VERSION ""

NS_ :

BS_:

BU_: DCU
VAL_TABLE_ OpCodeInfo 3 "MaxOpCodeIndex" 2 "SnrsFaultCodes" 1 "HWFaultCodes" 0 "InverterState" ;
VAL_TABLE_ OpCodeSignal 11 "MaxOpCodeIndex" 10 "DQAxesVoltages" 9 "PowerMeterInfo" 8 "PhaseVoltages" 7 "DQAxesCurrents" 6 "SpeedRefFdbck" 5 "TorqueRefFdbck" 4 "SpeedAndPosition" 3 "MeasuredVoltages" 2 "MeasuredCurrents" 1 "ExternalTemper" 0 "InternalTemper" ;

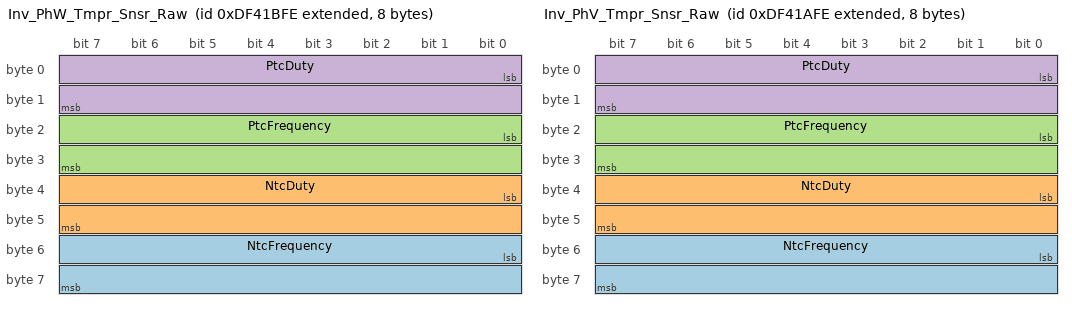
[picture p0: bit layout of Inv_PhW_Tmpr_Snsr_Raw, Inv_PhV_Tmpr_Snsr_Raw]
BO_ 2381585406 Inv_PhW_Tmpr_Snsr_Raw: 8 Vector__XXX
 SG_ NtcFrequency : 48|16@1+ (1,0) [0|65535] "" Vector__XXX
 SG_ NtcDuty : 32|16@1+ (1,0) [0|65535] "" Vector__XXX
 SG_ PtcFrequency : 16|16@1+ (1,0) [0|65535] "" Vector__XXX
 SG_ PtcDuty : 0|16@1+ (1,0) [0|65535] "" Vector__XXX

BO_ 2381585150 Inv_PhV_Tmpr_Snsr_Raw: 8 Vector__XXX
 SG_ NtcFrequency : 48|16@1+ (1,0) [0|65535] "" Vector__XXX
 SG_ NtcDuty : 32|16@1+ (1,0) [0|65535] "" Vector__XXX
 SG_ PtcFrequency : 16|16@1+ (1,0) [0|65535] "" Vector__XXX
 SG_ PtcDuty : 0|16@1+ (1,0) [0|65535] "" Vector__XXX

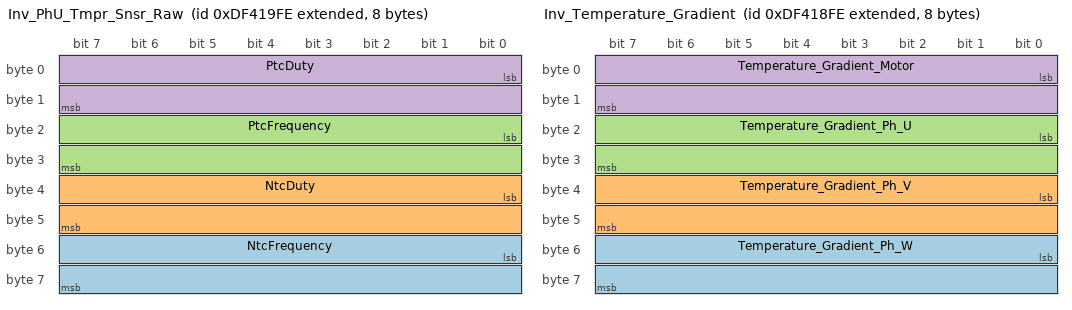
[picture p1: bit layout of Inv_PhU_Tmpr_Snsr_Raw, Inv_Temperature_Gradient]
BO_ 2381584894 Inv_PhU_Tmpr_Snsr_Raw: 8 Vector__XXX
 SG_ NtcFrequency : 48|16@1+ (1,0) [0|65535] "" Vector__XXX
 SG_ NtcDuty : 32|16@1+ (1,0) [0|65535] "" Vector__XXX
 SG_ PtcFrequency : 16|16@1+ (1,0) [0|65535] "" Vector__XXX
 SG_ PtcDuty : 0|16@1+ (1,0) [0|65535] "" Vector__XXX

BO_ 2381584638 Inv_Temperature_Gradient: 8 Vector__XXX
 SG_ Temperature_Gradient_Ph_W : 48|16@1+ (0.01,-327.68) [-327.68|327.67] "" Vector__XXX
 SG_ Temperature_Gradient_Ph_V : 32|16@1+ (0.01,-327.68) [-327.68|327.67] "" Vector__XXX
 SG_ Temperature_Gradient_Ph_U : 16|16@1+ (0.01,-327.68) [-327.68|327.67] "" Vector__XXX
 SG_ Temperature_Gradient_Motor : 0|16@1+ (0.01,-327.68) [-327.68|327.67] "" Vector__XXX

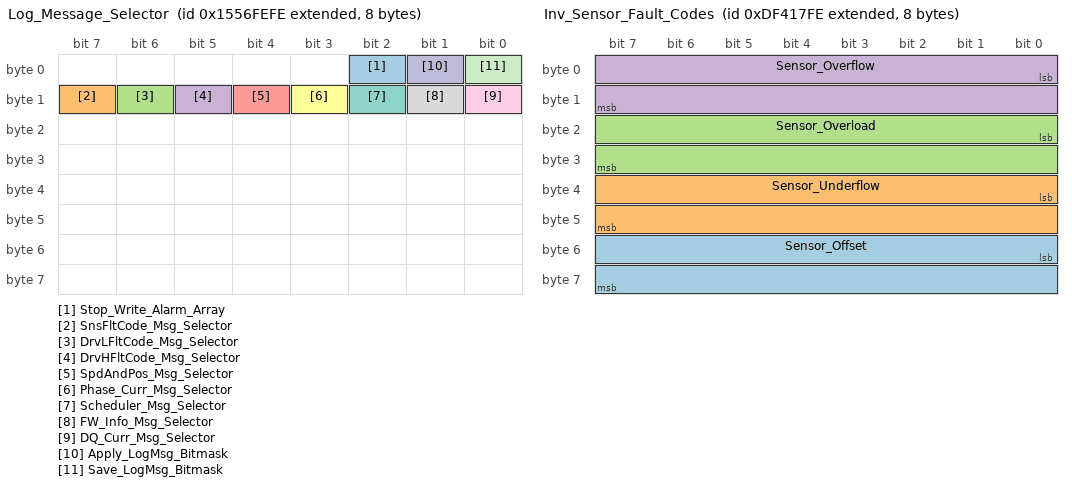
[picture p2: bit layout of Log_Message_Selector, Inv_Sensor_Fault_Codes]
BO_ 2505506558 Log_Message_Selector: 8 Vector__XXX
 SG_ Stop_Write_Alarm_Array : 2|1@1+ (1,0) [0|1] "" Vector__XXX
 SG_ SnsFltCode_Msg_Selector : 15|1@1+ (1,0) [0|1] "" Vector__XXX
 SG_ DrvLFltCode_Msg_Selector : 14|1@1+ (1,0) [0|1] "" Vector__XXX
 SG_ DrvHFltCode_Msg_Selector : 13|1@1+ (1,0) [0|1] "" Vector__XXX
 SG_ SpdAndPos_Msg_Selector : 12|1@1+ (1,0) [0|1] "" Vector__XXX
 SG_ Phase_Curr_Msg_Selector : 11|1@1+ (1,0) [0|1] "" Vector__XXX
 SG_ Scheduler_Msg_Selector : 10|1@1+ (1,0) [0|1] "" Vector__XXX
 SG_ FW_Info_Msg_Selector : 9|1@1+ (1,0) [0|1] "" Vector__XXX
 SG_ DQ_Curr_Msg_Selector : 8|1@1+ (1,0) [0|1] "" Vector__XXX
 SG_ Apply_LogMsg_Bitmask : 1|1@1+ (1,0) [0|1] "" Vector__XXX
 SG_ Save_LogMsg_Bitmask : 0|1@1+ (1,0) [0|1] "" Vector__XXX

BO_ 2381584382 Inv_Sensor_Fault_Codes: 8 Vector__XXX
 SG_ Sensor_Offset : 48|16@1+ (1,0) [0|65535] "" Vector__XXX
 SG_ Sensor_Underflow : 32|16@1+ (1,0) [0|65535] "" Vector__XXX
 SG_ Sensor_Overload : 16|16@1+ (1,0) [0|65535] "" Vector__XXX
 SG_ Sensor_Overflow : 0|16@1+ (1,0) [0|65535] "" Vector__XXX

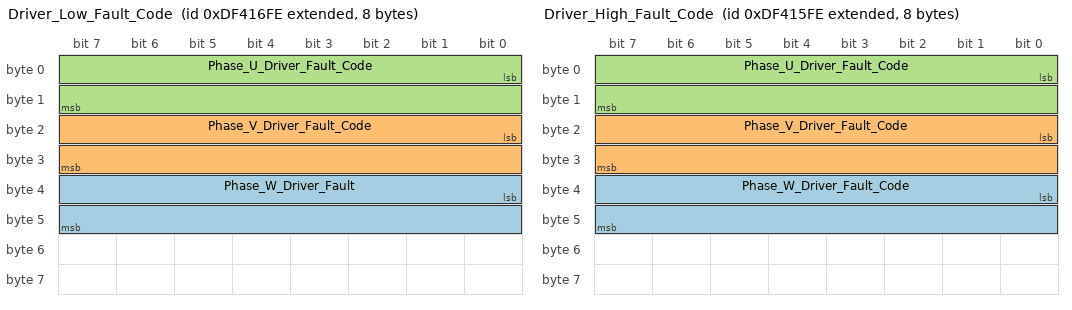
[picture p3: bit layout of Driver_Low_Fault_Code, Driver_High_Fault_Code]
BO_ 2381584126 Driver_Low_Fault_Code: 8 Vector__XXX
 SG_ Phase_W_Driver_Fault : 32|16@1+ (1,0) [0|65535] "" Vector__XXX
 SG_ Phase_V_Driver_Fault_Code : 16|16@1+ (1,0) [0|65535] "" Vector__XXX
 SG_ Phase_U_Driver_Fault_Code : 0|16@1+ (1,0) [0|65535] "" Vector__XXX

BO_ 2381583870 Driver_High_Fault_Code: 8 Vector__XXX
 SG_ Phase_W_Driver_Fault_Code : 32|16@1+ (1,0) [0|65535] "" Vector__XXX
 SG_ Phase_V_Driver_Fault_Code : 16|16@1+ (1,0) [0|65535] "" Vector__XXX
 SG_ Phase_U_Driver_Fault_Code : 0|16@1+ (1,0) [0|65535] "" Vector__XXX

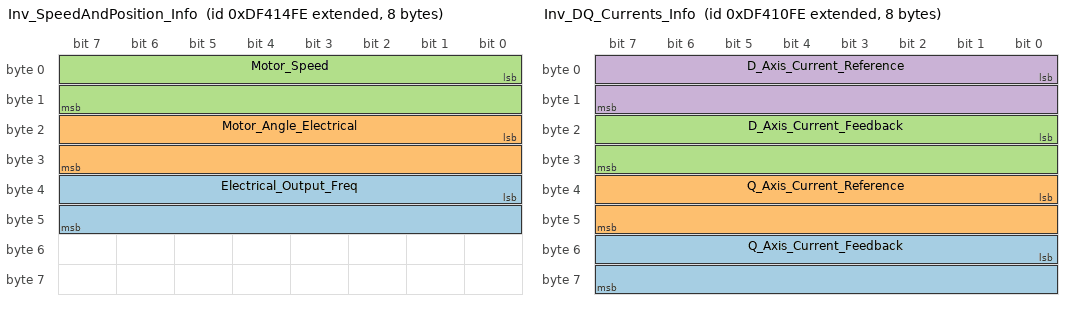
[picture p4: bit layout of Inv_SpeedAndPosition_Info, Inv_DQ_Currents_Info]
BO_ 2381583614 Inv_SpeedAndPosition_Info: 8 Vector__XXX
 SG_ Electrical_Output_Freq : 32|16@1+ (0.1,-3276.8) [-3148|3148] "Hz" Vector__XXX
 SG_ Motor_Angle_Electrical : 16|16@1+ (1,0) [0|4096] "deg/12bit" Vector__XXX
 SG_ Motor_Speed : 0|16@1+ (1,-32768) [-32760|32760] "rpm" Vector__XXX

BO_ 2381582590 Inv_DQ_Currents_Info: 8 Vector__XXX
 SG_ Q_Axis_Current_Feedback : 48|16@1+ (0.1,-3276.8) [-3148|3148] "Amps" Vector__XXX
 SG_ Q_Axis_Current_Reference : 32|16@1+ (0.1,-3276.8) [-3148|3148] "Amps" Vector__XXX
 SG_ D_Axis_Current_Feedback : 16|16@1+ (0.1,-3276.8) [-3148|3148] "Amps" Vector__XXX
 SG_ D_Axis_Current_Reference : 0|16@1+ (0.1,-3276.8) [-3148|3148] "Amps" Vector__XXX

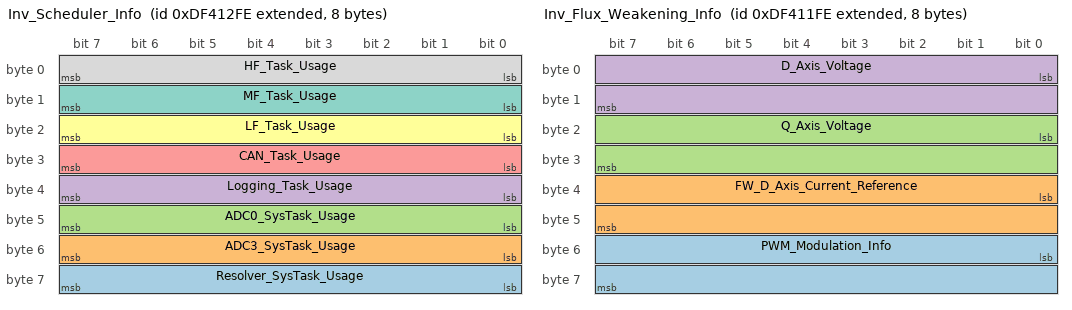
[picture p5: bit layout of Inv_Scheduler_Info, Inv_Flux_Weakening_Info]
BO_ 2381583102 Inv_Scheduler_Info: 8 Vector__XXX
 SG_ Resolver_SysTask_Usage : 56|8@1+ (0.5,0) [0|127.5] "%" Vector__XXX
 SG_ ADC3_SysTask_Usage : 48|8@1+ (0.5,0) [0|127.5] "%" Vector__XXX
 SG_ ADC0_SysTask_Usage : 40|8@1+ (0.5,0) [0|127.5] "%" Vector__XXX
 SG_ Logging_Task_Usage : 32|8@1+ (0.5,0) [0|127.5] "%" Vector__XXX
 SG_ CAN_Task_Usage : 24|8@1+ (0.5,0) [0|127.5] "%" Vector__XXX
 SG_ LF_Task_Usage : 16|8@1+ (0.5,0) [0|127.5] "%" Vector__XXX
 SG_ MF_Task_Usage : 8|8@1+ (0.5,0) [0|127.5] "%" Vector__XXX
 SG_ HF_Task_Usage : 0|8@1+ (0.5,0) [0|127.5] "%" Vector__XXX

BO_ 2381582846 Inv_Flux_Weakening_Info: 8 Vector__XXX
 SG_ PWM_Modulation_Info : 48|16@1+ (1,0) [0|32767] "" Vector__XXX
 SG_ FW_D_Axis_Current_Reference : 32|16@1+ (0.1,-3276.8) [-3148|3148] "Amps" Vector__XXX
 SG_ Q_Axis_Voltage : 16|16@1+ (0.1,-3276.8) [-3148|3148] "V" Vector__XXX
 SG_ D_Axis_Voltage : 0|16@1+ (0.1,-3276.8) [-3148|3148] "V" Vector__XXX

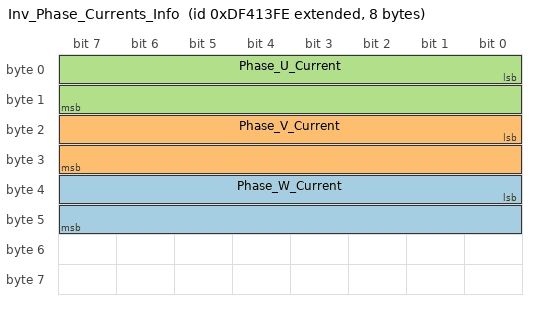
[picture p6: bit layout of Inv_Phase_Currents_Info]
BO_ 2381583358 Inv_Phase_Currents_Info: 8 Vector__XXX
 SG_ Phase_W_Current : 32|16@1+ (0.1,-3276.8) [-3148|3148] "Amps" Vector__XXX
 SG_ Phase_V_Current : 16|16@1+ (0.1,-3276.8) [-3148|3148] "Amps" Vector__XXX
 SG_ Phase_U_Current : 0|16@1+ (0.1,-3276.8) [-3148|3148] "Amps" Vector__XXX

CM_ BO_ 2381585406 "Phase temperature sensors raw values";
CM_ SG_ 2381585406 NtcFrequency "Frequency of the PWM signal of the PTC temperature sensor";
CM_ SG_ 2381585406 NtcDuty "Duty of the PWM signal of the NTC temperature sensor";
CM_ SG_ 2381585406 PtcFrequency "Frequency of the PWM signal of the PTC temperature sensor";
CM_ SG_ 2381585406 PtcDuty "Duty of the PWM signal of the PTC temperature sensor";
CM_ BO_ 2381585150 "Phase temperature sensors raw values";
CM_ SG_ 2381585150 NtcFrequency "Frequency of the PWM signal of the PTC temperature sensor";
CM_ SG_ 2381585150 NtcDuty "Duty of the PWM signal of the NTC temperature sensor";
CM_ SG_ 2381585150 PtcFrequency "Frequency of the PWM signal of the PTC temperature sensor";
CM_ SG_ 2381585150 PtcDuty "Duty of the PWM signal of the PTC temperature sensor";
CM_ BO_ 2381584894 "Phase temperature sensors raw values";
CM_ SG_ 2381584894 NtcFrequency "Frequency of the PWM signal of the PTC temperature sensor";
CM_ SG_ 2381584894 NtcDuty "Duty of the PWM signal of the NTC temperature sensor";
CM_ SG_ 2381584894 PtcFrequency "Frequency of the PWM signal of the PTC temperature sensor";
CM_ SG_ 2381584894 PtcDuty "Duty of the PWM signal of the PTC temperature sensor";
CM_ BO_ 2381584638 "Inverter sensors fault codes";
CM_ SG_ 2381584638 Temperature_Gradient_Ph_W "Temperature gradient of IGBT phase W";
CM_ SG_ 2381584638 Temperature_Gradient_Ph_V "Temperature gradient of IGBT phase V";
CM_ SG_ 2381584638 Temperature_Gradient_Ph_U "Temperature gradient of IGBT phase U";
CM_ SG_ 2381584638 Temperature_Gradient_Motor "Temperature gradient of motor";
CM_ BO_ 2505506558 "Log messages control";
CM_ SG_ 2505506558 Stop_Write_Alarm_Array "Command stop writing alarm array to FRAM";
CM_ SG_ 2505506558 SnsFltCode_Msg_Selector "ON/OFF signal of message Inv_Sensor_Fault_Codes";
CM_ SG_ 2505506558 DrvLFltCode_Msg_Selector "ON/OFF signal of message Driver_Low_Fault_Code";
CM_ SG_ 2505506558 DrvHFltCode_Msg_Selector "ON/OFF signal of message Driver_High_Fault_Code";
CM_ SG_ 2505506558 SpdAndPos_Msg_Selector "ON/OFF signal of message Inv_SpeedAndPosition_Info";
CM_ SG_ 2505506558 Phase_Curr_Msg_Selector "ON/OFF signal of message Inv_Phase_Currents_Info";
CM_ SG_ 2505506558 Scheduler_Msg_Selector "ON/OFF signal of message Inv_Scheduller_Info";
CM_ SG_ 2505506558 FW_Info_Msg_Selector "ON/OFF signal of message Inv_Flux_Weakening_Info";
CM_ SG_ 2505506558 DQ_Curr_Msg_Selector "ON/OFF signal of message Inv_DQ_Currents_Info";
CM_ SG_ 2505506558 Apply_LogMsg_Bitmask "This signal commands inverter to apply logging message bitmask";
CM_ SG_ 2505506558 Save_LogMsg_Bitmask "This signal commands inverter to save logging message bitmask to NVRAM";
CM_ BO_ 2381584382 "Inverter sensors fault codes";
CM_ SG_ 2381584382 Sensor_Offset "Each bit represents sensor offset fault. Please refer to documentation for details.";
CM_ SG_ 2381584382 Sensor_Underflow "Each bit represents sensor underflow fault. Please refer to documentation for details.";
CM_ SG_ 2381584382 Sensor_Overload "Each bit represents sensor overload fault. Please refer to documentation for details.";
CM_ SG_ 2381584382 Sensor_Overflow "Each bit represents sensor overflow fault. Please refer to documentation for details.";
CM_ BO_ 2381584126 "Fault codes of low IGBTs in 3-phase inverter assemble";
CM_ SG_ 2381584126 Phase_W_Driver_Fault "Phase V driver fault code.";
CM_ SG_ 2381584126 Phase_V_Driver_Fault_Code "Phase V driver fault code.";
CM_ SG_ 2381584126 Phase_U_Driver_Fault_Code "Phase U driver fault code.";
CM_ BO_ 2381583870 "Fault codes of high IGBTs in 3-phase inverter assemble";
CM_ SG_ 2381583870 Phase_W_Driver_Fault_Code "Phase V driver fault code.";
CM_ SG_ 2381583870 Phase_V_Driver_Fault_Code "Phase V driver fault code.";
CM_ SG_ 2381583870 Phase_U_Driver_Fault_Code "Phase U driver fault code.";
CM_ BO_ 2381583614 "Motor speed and position information";
CM_ SG_ 2381583614 Electrical_Output_Freq "Calculated value of the output electrical frequency";
CM_ SG_ 2381583614 Motor_Angle_Electrical "Measured value of the motor rotor electrical angle";
CM_ SG_ 2381583614 Motor_Speed "Calculated value of the motor rotor speed";
CM_ BO_ 2381582590 "DQ-axes reference and feedback currents";
CM_ SG_ 2381582590 Q_Axis_Current_Feedback "Measured output Q-axis current";
CM_ SG_ 2381582590 Q_Axis_Current_Reference "Reference Q-axis current value";
CM_ SG_ 2381582590 D_Axis_Current_Feedback "Measured output D-axis current";
CM_ SG_ 2381582590 D_Axis_Current_Reference "Reference D-axis current value";
CM_ BO_ 2381583102 "Scheduler task utilization info";
CM_ SG_ 2381583102 Resolver_SysTask_Usage "Percentage of Resolver system task usage";
CM_ SG_ 2381583102 ADC3_SysTask_Usage "Percentage of ADC channel 3 system task usage";
CM_ SG_ 2381583102 ADC0_SysTask_Usage "Percentage of ADC channel 0 system task usage";
CM_ SG_ 2381583102 Logging_Task_Usage "Percentage of Logging task usage";
CM_ SG_ 2381583102 CAN_Task_Usage "Percentage of CAN task usage";
CM_ SG_ 2381583102 LF_Task_Usage "Percentage of Low Frequency task usage";
CM_ SG_ 2381583102 MF_Task_Usage "Percentage of Medium Frequency task usage";
CM_ SG_ 2381583102 HF_Task_Usage "Percentage of High Frequency task usage";
CM_ BO_ 2381582846 "Flux Weakening algorithm values";
CM_ SG_ 2381582846 PWM_Modulation_Info "PWM modulation voltage amplitude (32767 - 100% amplitude value)";
CM_ SG_ 2381582846 FW_D_Axis_Current_Reference "Reference value D-axis current component";
CM_ SG_ 2381582846 Q_Axis_Voltage "Calculated output Q-axis voltage";
CM_ SG_ 2381582846 D_Axis_Voltage "Calculated output D-axis voltage";
CM_ BO_ 2381583358 "Inverter measured phase currents";
CM_ SG_ 2381583358 Phase_W_Current "Phase W measured current";
CM_ SG_ 2381583358 Phase_V_Current "Phase V measured current";
CM_ SG_ 2381583358 Phase_U_Current "Phase U measured current";
BA_DEF_ BO_  "PpCcGenMsgType" STRING ;
BA_DEF_ SG_  "SigType" ENUM  "Default","Range","RangeSigned","ASCII","Discrete","Control","ReferencePGN","DTC","StringDelimiter","StringLength","StringLengthControl","MessageCounter","MessageChecksum";
BA_DEF_ SG_  "GenSigEVName" STRING ;
BA_DEF_ SG_  "GenSigILSupport" ENUM  "No","Yes";
BA_DEF_ SG_  "GenSigSendType" ENUM  "Cyclic","OnWrite","OnWriteWithRepetition","OnChange","OnChangeWithRepetition","IfActive","IfActiveWithRepetition","NoSigSendType";
BA_DEF_ SG_  "GenSigStartValue" INT 0 2147483647;
BA_DEF_ BO_  "GenMsgILSupport" ENUM  "No","Yes";
BA_DEF_ BU_  "NmStationAddress" INT 0 255;
BA_DEF_ BO_  "GenMsgSendType" ENUM  "cyclic","NotUsed","IfActive","NotUsed","NotUsed","NotUsed","NotUsed","NotUsed","noMsgSendType";
BA_DEF_ BO_  "GenMsgRequestable" INT 0 1;
BA_DEF_ BO_  "GenMsgCycleTime" INT 0 3600000;
BA_DEF_  "DBName" STRING ;
BA_DEF_  "BusType" STRING ;
BA_DEF_  "ProtocolType" STRING ;
BA_DEF_ BO_  "VFrameFormat" ENUM  "StandardCAN","ExtendedCAN","reserved","J1939PG";
BA_DEF_DEF_  "PpCcGenMsgType" "PpCcUndefined";
BA_DEF_DEF_  "SigType" "Default";
BA_DEF_DEF_  "GenSigEVName" "Env@Nodename_@Signame";
BA_DEF_DEF_  "GenSigILSupport" "Yes";
BA_DEF_DEF_  "GenSigSendType" "NoSigSendType";
BA_DEF_DEF_  "GenSigStartValue" 0;
BA_DEF_DEF_  "GenMsgILSupport" "Yes";
BA_DEF_DEF_  "NmStationAddress" 254;
BA_DEF_DEF_  "GenMsgSendType" "noMsgSendType";
BA_DEF_DEF_  "GenMsgRequestable" 1;
BA_DEF_DEF_  "GenMsgCycleTime" 0;
BA_DEF_DEF_  "DBName" "";
BA_DEF_DEF_  "BusType" "CAN";
BA_DEF_DEF_  "ProtocolType" "J1939";
BA_DEF_DEF_  "VFrameFormat" "J1939PG";
BA_ "DBName" "Traction_Inverter";
BA_ "NmStationAddress" BU_ DCU 100;
BA_ "PpCcGenMsgType" BO_ 2381585406 "PpCcUnused";
BA_ "GenMsgCycleTime" BO_ 2381585406 100;
BA_ "PpCcGenMsgType" BO_ 2381585150 "PpCcUnused";
BA_ "GenMsgCycleTime" BO_ 2381585150 100;
BA_ "PpCcGenMsgType" BO_ 2381584894 "PpCcUnused";
BA_ "GenMsgCycleTime" BO_ 2381584894 100;
BA_ "PpCcGenMsgType" BO_ 2381584638 "PpCcUnused";
BA_ "GenMsgCycleTime" BO_ 2381584638 100;
BA_ "PpCcGenMsgType" BO_ 2505506558 "PpCcInput";
BA_ "PpCcGenMsgType" BO_ 2381584382 "PpCcOutput";
BA_ "GenMsgCycleTime" BO_ 2381584382 100;
BA_ "PpCcGenMsgType" BO_ 2381584126 "PpCcOutput";
BA_ "GenMsgCycleTime" BO_ 2381584126 1000;
BA_ "PpCcGenMsgType" BO_ 2381583870 "PpCcOutput";
BA_ "GenMsgCycleTime" BO_ 2381583870 1000;
BA_ "PpCcGenMsgType" BO_ 2381583614 "PpCcOutput";
BA_ "GenMsgCycleTime" BO_ 2381583614 10;
BA_ "PpCcGenMsgType" BO_ 2381582590 "PpCcOutput";
BA_ "GenMsgCycleTime" BO_ 2381582590 10;
BA_ "PpCcGenMsgType" BO_ 2381583102 "PpCcOutput";
BA_ "GenMsgCycleTime" BO_ 2381583102 1000;
BA_ "PpCcGenMsgType" BO_ 2381582846 "PpCcOutput";
BA_ "GenMsgCycleTime" BO_ 2381582846 10;
BA_ "PpCcGenMsgType" BO_ 2381583358 "PpCcOutput";
BA_ "GenMsgCycleTime" BO_ 2381583358 10;
BA_ "GenSigStartValue" SG_ 2381584638 Temperature_Gradient_Ph_W 32768;
BA_ "GenSigStartValue" SG_ 2381584638 Temperature_Gradient_Ph_V 32768;
BA_ "GenSigStartValue" SG_ 2381584638 Temperature_Gradient_Ph_U 32768;
BA_ "GenSigStartValue" SG_ 2381584638 Temperature_Gradient_Motor 32768;
BA_ "GenSigStartValue" SG_ 2381583614 Electrical_Output_Freq 32768;
BA_ "GenSigStartValue" SG_ 2381583614 Motor_Speed 32768;
BA_ "SigType" SG_ 2381582590 Q_Axis_Current_Feedback 1;
BA_ "GenSigStartValue" SG_ 2381582590 Q_Axis_Current_Feedback 32768;
BA_ "SigType" SG_ 2381582590 Q_Axis_Current_Reference 1;
BA_ "GenSigStartValue" SG_ 2381582590 Q_Axis_Current_Reference 32768;
BA_ "SigType" SG_ 2381582590 D_Axis_Current_Feedback 1;
BA_ "GenSigStartValue" SG_ 2381582590 D_Axis_Current_Feedback 32768;
BA_ "SigType" SG_ 2381582590 D_Axis_Current_Reference 1;
BA_ "GenSigStartValue" SG_ 2381582590 D_Axis_Current_Reference 32768;
BA_ "SigType" SG_ 2381582846 FW_D_Axis_Current_Reference 1;
BA_ "GenSigStartValue" SG_ 2381582846 FW_D_Axis_Current_Reference 32768;
BA_ "SigType" SG_ 2381582846 Q_Axis_Voltage 1;
BA_ "GenSigStartValue" SG_ 2381582846 Q_Axis_Voltage 32768;
BA_ "GenSigStartValue" SG_ 2381582846 D_Axis_Voltage 32768;
BA_ "SigType" SG_ 2381582846 D_Axis_Voltage 1;
BA_ "GenSigStartValue" SG_ 2381583358 Phase_W_Current 32768;
BA_ "SigType" SG_ 2381583358 Phase_W_Current 1;
BA_ "GenSigStartValue" SG_ 2381583358 Phase_V_Current 32768;
BA_ "SigType" SG_ 2381583358 Phase_V_Current 1;
BA_ "GenSigStartValue" SG_ 2381583358 Phase_U_Current 32768;
BA_ "SigType" SG_ 2381583358 Phase_U_Current 1;
VAL_ 2505506558 SnsFltCode_Msg_Selector 1 "Msg_ON" 0 "Msg_OFF" ;
VAL_ 2505506558 DrvLFltCode_Msg_Selector 1 "Msg_ON" 0 "Msg_OFF" ;
VAL_ 2505506558 DrvHFltCode_Msg_Selector 1 "Msg_ON" 0 "Msg_OFF" ;
VAL_ 2505506558 SpdAndPos_Msg_Selector 1 "Msg_ON" 0 "Msg_OFF" ;
VAL_ 2505506558 Phase_Curr_Msg_Selector 1 "Msg_ON" 0 "Msg_OFF" ;
VAL_ 2505506558 Scheduler_Msg_Selector 1 "Msg_ON" 0 "Msg_OFF" ;
VAL_ 2505506558 FW_Info_Msg_Selector 1 "Msg_ON" 0 "Msg_OFF" ;
VAL_ 2505506558 DQ_Curr_Msg_Selector 1 "Msg_ON" 0 "Msg_OFF" ;
